AUTOSAR XML (schema 4-2-1)
package /RootP_ASWC_A7D2
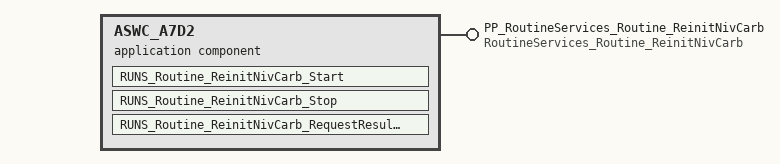
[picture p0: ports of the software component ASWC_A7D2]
  application sw component type ASWC_A7D2
    provide port PP_RoutineServices_Routine_ReinitNivCarb: provided-interface=RoutineServices_Routine_ReinitNivCarb
      provided-com-specs:
        operation=Start, queue-length=1
        operation=Stop, queue-length=1
        operation=RequestResults, queue-length=1
    behavior IB_ASWC_A7D2: data-type-mapping=ApplicationModeMapping, handle-termination-and-restart=NO-SUPPORT
      operation invoked event RoutineServices_Routine_ReinitNivCarb_Start_OIE: start-on-event=RUNS_Routine_ReinitNivCarb_Start, operation=PP_RoutineServices_Routine_ReinitNivCarb.Start
      operation invoked event RoutineServices_Routine_ReinitNivCarb_Stop_OIE: start-on-event=RUNS_Routine_ReinitNivCarb_Stop, operation=PP_RoutineServices_Routine_ReinitNivCarb.Stop
      operation invoked event RoutineServices_Routine_ReinitNivCarb_RequestResults_OIE: start-on-event=RUNS_Routine_ReinitNivCarb_RequestResults, operation=PP_RoutineServices_Routine_ReinitNivCarb.RequestResults
      runnable RUNS_Routine_ReinitNivCarb_Start
      runnable RUNS_Routine_ReinitNivCarb_Stop
      runnable RUNS_Routine_ReinitNivCarb_RequestResults
package /AUTOSAR_Dcm/PortInterfaces
  6 x client server interface, all with is-service=true:
    DataServices_DcmDspData_DID_CAPA_RESERVOIR
      operation ReadData
        arg Data: type=tBYTE, direction=OUT
      operation WriteData
        arg Data: type=tBYTE, direction=IN
        arg ErrorCode: type=tBYTE, direction=OUT
    DataServices_DcmDspData_DID_LOI_JAUGE_NIV_ALERTE
      operation ReadData
        arg Data: type=tBYTE, direction=OUT
      operation WriteData
        arg Data: type=tBYTE, direction=IN
        arg ErrorCode: type=tBYTE, direction=OUT
    DataServices_DcmDspData_DID_NivCarbAffiche
      operation ReadData
        arg Data: type=tBYTE, direction=OUT
    DataServices_DcmDspData_DID_NIV_CARB_CRITIQUE
      operation ReadData
        arg Data: type=tBYTE, direction=OUT
      operation WriteData
        arg Data: type=tBYTE, direction=IN
        arg ErrorCode: type=tBYTE, direction=OUT
    DataServices_DcmDspData_DID_NivCarbRestant
      operation ReadData
        arg Data: type=tBYTE, direction=OUT
    RoutineServices_Routine_ReinitNivCarb
      operation Start
        4 x arg, all with type=uint8:
          dataIn0: direction=IN
          dataOut0: direction=OUT
          ErrorCode: direction=OUT
          OpStatus: direction=IN
      operation Stop
        4 x arg, all with type=uint8:
          dataIn0: direction=IN
          dataOut0: direction=OUT
          ErrorCode: direction=OUT
          OpStatus: direction=IN
      operation RequestResults
        arg dataOut0: type=uint8, direction=OUT
        arg ErrorCode: type=uint8, direction=OUT
        arg OpStatus: type=uint8, direction=IN
